# GD32L235x register map
File version: 1.0
CPU: CM23 r1p0, little endian, no MPU, no FPU, 2 interrupt priority bits
Registers are 32-bit, read-write, reset 0x0 unless marked. A register's access mark holds for its fields unless they carry their own. Offsets are from the block's base; [hi:lo] are bit positions; {n}, {i} and the like mark numbered series; 'fields as' and 'values as' point back to an identical list.

## SPI1 — Serial Peripheral Interface 1
Base 0x40003800
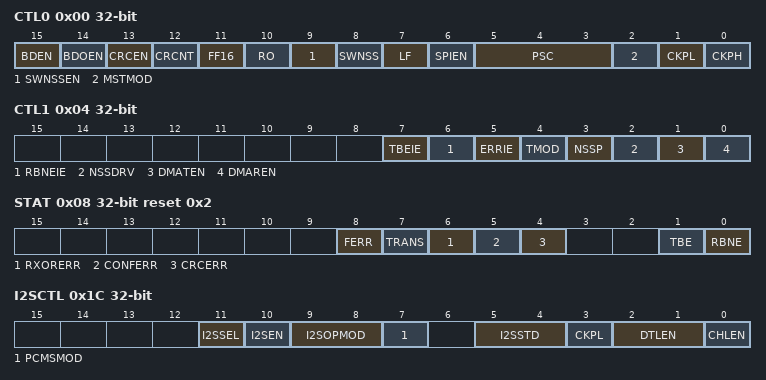
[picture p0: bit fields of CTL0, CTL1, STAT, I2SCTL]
0x00 CTL0 — control register 0
  [15] BDEN — Bidirectional enable
  [14] BDOEN — Bidirectional Transmit output enable
  [13] CRCEN — Hardware CRC calculation enable
  [12] CRCNT — CRC transfer next
  [11] FF16 — Data frame format
  [10] RO — Receive only
  [9] SWNSSEN — NSS Software Mode Selection
  [8] SWNSS — NSS Pin Selection In NSS Software Mode
  [7] LF — LSB First Mode
  [6] SPIEN — SPI enable
  [5:3] PSC — Master Clock Prescaler Selection
  [2] MSTMOD — Master Mode Enable
  [1] CKPL — Clock Polarity Selection
  [0] CKPH — Clock Phase Selection
0x04 CTL1 — control register 1
  [7] TBEIE — Transmit Buffer Empty Interrupt Enable
  [6] RBNEIE — Receive Buffer Not Empty Interrupt Enable
  [5] ERRIE — Error interrupt enable
  [4] TMOD — SPI TI Mode Enable
  [3] NSSP — SPI NSS Pulse Mode Enable
  [2] NSSDRV — NSS output enable
  [1] DMATEN — Tx buffer DMA enable
  [0] DMAREN — Rx buffer DMA enable
0x08 STAT access per field reset 0x2 — status register
  [8] FERR rw — Format Error
  [7] TRANS ro — Transmitting On-going Bit
  [6] RXORERR ro — Reception Overrun Error Bit
  [5] CONFERR ro — SPI Configuration error
  [4] CRCERR rw — SPI CRC Error Bit
  [1] TBE ro — Transmit Buffer Empty
  [0] RBNE ro — Receive Buffer Not Empty
0x0C DATA
  [15:0] DATA
0x10 CPCPOLY reset 0x7 — CRC polynomial register
  [15:0] CRCPOLY
0x14 RCRC ro — RX CRC register
  [15:0] RCRC — RX RCR register
0x18 TCRC ro — TX CRC register
  [15:0] TCRC — Tx CRC register
0x1C I2SCTL — I2S configuration register
  [11] I2SSEL — I2S mode selection
  [10] I2SEN — I2S Enable
  [9:8] I2SOPMOD — I2S configuration mode
  [7] PCMSMOD — PCM frame synchronization
  [5:4] I2SSTD — I2S standard selection
  [3] CKPL — Idle state clock polarity
  [2:1] DTLEN — Data length to be transferred
  [0] CHLEN — Channel length (number of bits per audio channel)
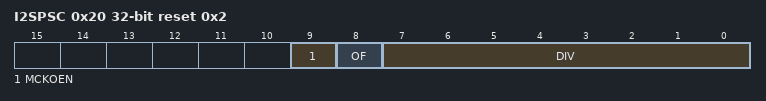
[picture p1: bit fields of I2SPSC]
0x20 I2SPSC reset 0x2 — I2S prescaler register
  [9] MCKOEN — I2S_MCK output enable
  [8] OF — Odd factor for the prescaler
  [7:0] DIV — Dividing factor for the prescaler

## SYSCFG — System configuration controller
Base 0x40010000
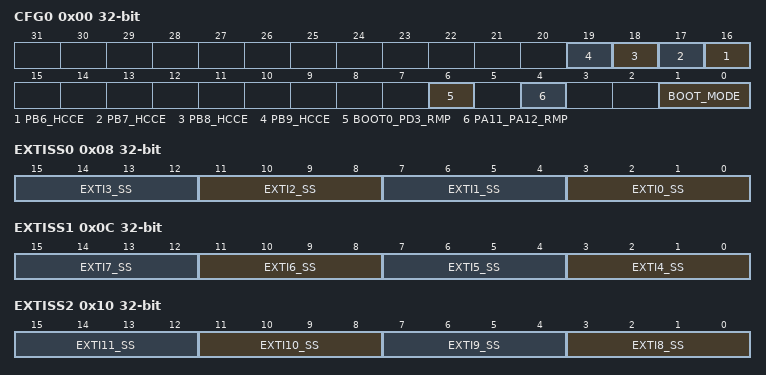
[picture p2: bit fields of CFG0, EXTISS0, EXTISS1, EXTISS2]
0x00 CFG0 — System configuration register 0
  [n+10] PB{n}_HCCE (n=6..9) — PB{n} pin high current capability enable
  [6] BOOT0_PD3_RMP — BOOT0 and PB9 remapping bit
  [4] PA11_PA12_RMP — PA11 and PA12 remapping bit for small packages
  [1:0] BOOT_MODE ro
0x08 EXTISS0 — EXTI sources selection register 0
  [4n+3:4n] EXTI{n}_SS (n=0..3) — EXTI {n} sources selection
0x0C EXTISS1 — EXTI sources selection register 1
  [4n-13:4n-16] EXTI{n}_SS (n=4..7) — EXTI {n} sources selection
0x10 EXTISS2 — EXTI sources selection register 2
  [4n-29:4n-32] EXTI{n}_SS (n=8..11) — EXTI {n} sources selection
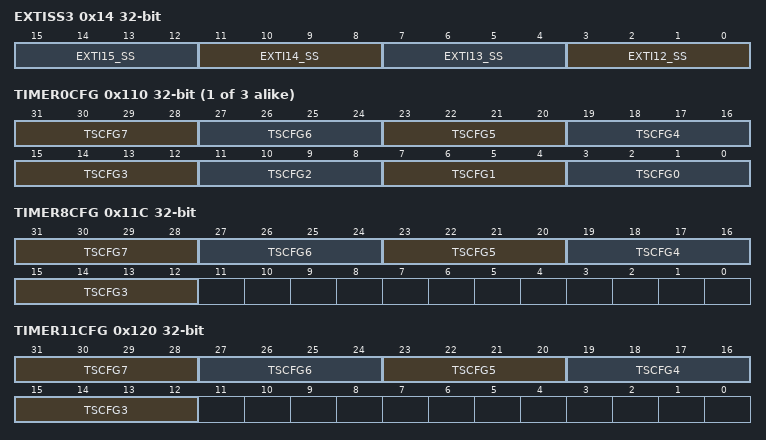
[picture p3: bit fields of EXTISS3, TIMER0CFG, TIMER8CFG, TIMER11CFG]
0x14 EXTISS3 — EXTI sources selection register 3
  [4n-45:4n-48] EXTI{n}_SS (n=12..15) — EXTI {n} sources selection
0x100 CPU_IRQ_LAT — IRQ Latency register
  [7:0] IRQ_LATENCY — specifies the minimum number of cycles between an interrupt
{0x110+4i} TIMER{i}CFG (i=0..2) — TIMER{i} configuration register
  [31:28] TSCFG7 — Channel input configuration
  [27:24] TSCFG6 — External clock mode 0 configuration
  [23:20] TSCFG5 — Event mode configuration
  [19:16] TSCFG4 — Pause mode configuration
  [15:12] TSCFG3 — Restart mode configuration
  [11:8] TSCFG2 — Quadrature decoder mode 2 configuration
  [7:4] TSCFG1 — Quadrature decoder mode 1 configuration
  [3:0] TSCFG0 — Quadrature decoder mode 0 configuration
0x11C TIMER8CFG — TIMER8 configuration register
  [31:28] TSCFG7 — Channel input configuration
  [27:24] TSCFG6 — External clock mode 0 configuration
  [23:20] TSCFG5 — Event mode configuration
  [19:16] TSCFG4 — Pause mode configuration
  [15:12] TSCFG3 — Restart mode configuration
0x120 TIMER11CFG — TIMER11 configuration register
  fields as TIMER8CFG
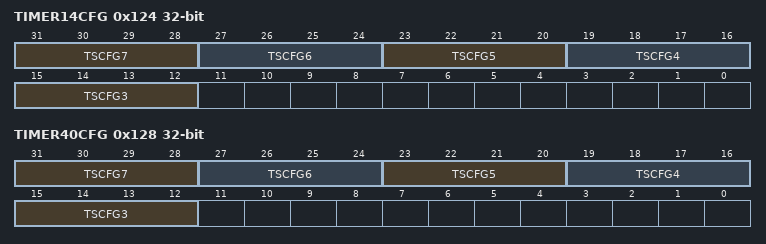
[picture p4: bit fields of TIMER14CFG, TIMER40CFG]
0x124 TIMER14CFG — TIMER14 configuration register
  fields as TIMER8CFG
0x128 TIMER40CFG — TIMER40 configuration register
  fields as TIMER8CFG
